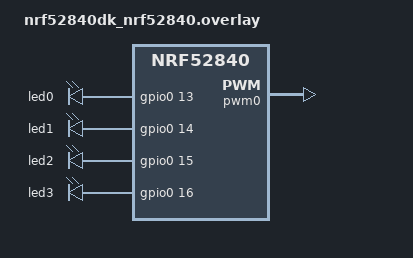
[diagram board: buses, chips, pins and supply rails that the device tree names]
/* Copyright (c) 2020 Nordic Semiconductor ASA
 *
 * SPDX-License-Identifier: LicenseRef-Nordic-5-Clause
 */

// To get started, press Ctrl+Space to bring up the completion menu and view the available nodes.

// You can also use the buttons in the sidebar to perform actions on nodes.
// Actions currently available include:

// * Enabling / disabling the node
// * Adding the bus to a bus
// * Removing the node
// * Connecting ADC channels

// For more help, browse the DeviceTree documentation at https://docs.zephyrproject.org/latest/guides/dts/index.html
// You can also visit the nRF DeviceTree extension documentation at https://nrfconnect.github.io/vscode-nrf-connect/devicetree/nrfdevicetree.html
/* old notation: 
&pwm0 {
    status = "okay";
    ch1-pin = <15>;
    /delete-property/ ch1-inverted;
}; */

#define MOTOR0PIN 4
#define MOTOR1PIN 3
#define MOTOR2PIN 5
/{
         
    aliases {
        motor0 = &motor_null;
    };

    chosen {
		zephyr,entropy = &rng;
	};

    motor_null: motor_driver_alt {
        /* This selects Driver B implementation */
        compatible = "loki,dummy-motor";
        status = "okay";
        /* Different resource types entirely */

    };
/* 
    motor_driver: motor_driver {
        compatible = "toshiba,tb67h453";
        pwms = <&pwm0 1 PWM_MSEC(20) PWM_POLARITY_NORMAL>,
               <&pwm0 2 PWM_MSEC(20) PWM_POLARITY_NORMAL>;
        sleep-gpios = <&gpio0 MOTOR0PIN GPIO_ACTIVE_HIGH>;
        status = "disabled";
    };
    */
};

&pinctrl {
    pwm0_default3: pwm0_default {
        group1 {
            psels = <NRF_PSEL(PWM_OUT1, 0, MOTOR1PIN)>,
                    <NRF_PSEL(PWM_OUT2, 0, MOTOR2PIN)>;
            low-power-enable;
        };
    };

    pwm0_sleep3: pwm0_sleep {
        group1 {
            psels = <NRF_PSEL(PWM_OUT1, 0, MOTOR1PIN)>,
                    <NRF_PSEL(PWM_OUT2, 0, MOTOR2PIN)>;
            low-power-enable;
        };
    };


};


&pwm0 {   
    pinctrl-0 = < &pwm0_default3 >;
    pinctrl-1 = < &pwm0_sleep3 >;
    pinctrl-names = "default", "sleep";
    status = "okay";
};

&gpio0 {
    status = "okay";
};
&led0 {
    gpios = <&gpio0 13 0>;
};

&led1 {
    gpios = <&gpio0 14 0>;
};

&led2 {
    gpios = <&gpio0 15 0>;
};

&led3 {
    gpios = <&gpio0 16 0>;
};

&i2c0_default {
    group1 {
        psels = <NRF_PSEL(TWIM_SDA, 0, 29)>, <NRF_PSEL(TWIM_SCL, 0, 2)>;
    };
};

&i2c0_sleep {
    group1 {
        psels = <NRF_PSEL(TWIM_SDA, 0, 29)>, <NRF_PSEL(TWIM_SCL, 0, 2)>;
    };
};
